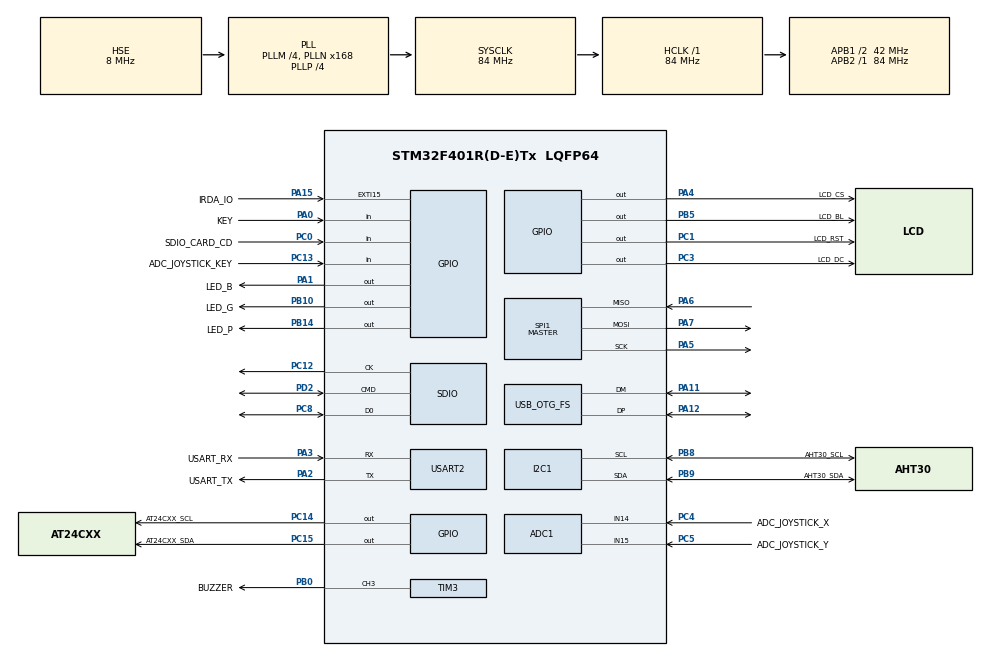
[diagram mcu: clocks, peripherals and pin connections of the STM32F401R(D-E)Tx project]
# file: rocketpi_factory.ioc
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ADC1.Channel-0\#ChannelRegularConversion=ADC_CHANNEL_14
ADC1.Channel-1\#ChannelRegularConversion=ADC_CHANNEL_15
ADC1.ContinuousConvMode=ENABLE
ADC1.EnableAnalogWatchDog=false
ADC1.InjNumberOfConversion=0
ADC1.NbrOfConversion=2
ADC1.NbrOfConversionFlag=1
ADC1.Rank-0\#ChannelRegularConversion=1
ADC1.Rank-1\#ChannelRegularConversion=2
ADC1.SamplingTime-0\#ChannelRegularConversion=ADC_SAMPLETIME_112CYCLES
ADC1.SamplingTime-1\#ChannelRegularConversion=ADC_SAMPLETIME_112CYCLES
ADC1.ScanConvMode=ENABLE
ADC1.master=1
Dma.Request0=SPI1_TX
Dma.Request1=SDIO_RX
Dma.Request2=SDIO_TX
Dma.Request3=USART2_RX
Dma.Request4=USART2_TX
Dma.SDIO_RX.1.Direction=DMA_PERIPH_TO_MEMORY
Dma.SDIO_RX.1.FIFOMode=DMA_FIFOMODE_ENABLE
Dma.SDIO_RX.1.FIFOThreshold=DMA_FIFO_THRESHOLD_FULL
Dma.SDIO_RX.1.Instance=DMA2_Stream6
Dma.SDIO_RX.1.MemBurst=DMA_MBURST_INC4
Dma.SDIO_RX.1.MemDataAlignment=DMA_MDATAALIGN_WORD
Dma.SDIO_RX.1.MemInc=DMA_MINC_ENABLE
Dma.SDIO_RX.1.Mode=DMA_PFCTRL
Dma.SDIO_RX.1.PeriphBurst=DMA_PBURST_INC4
Dma.SDIO_RX.1.PeriphDataAlignment=DMA_PDATAALIGN_WORD
Dma.SDIO_RX.1.PeriphInc=DMA_PINC_DISABLE
Dma.SDIO_RX.1.Priority=DMA_PRIORITY_LOW
Dma.SDIO_TX.2.Direction=DMA_MEMORY_TO_PERIPH
Dma.SDIO_TX.2.FIFOMode=DMA_FIFOMODE_ENABLE
Dma.SDIO_TX.2.FIFOThreshold=DMA_FIFO_THRESHOLD_FULL
Dma.SDIO_TX.2.Instance=DMA2_Stream3
Dma.SDIO_TX.2.MemBurst=DMA_MBURST_INC4
Dma.SDIO_TX.2.MemDataAlignment=DMA_MDATAALIGN_WORD
Dma.SDIO_TX.2.MemInc=DMA_MINC_ENABLE
Dma.SDIO_TX.2.Mode=DMA_PFCTRL
Dma.SDIO_TX.2.PeriphBurst=DMA_PBURST_INC4
Dma.SDIO_TX.2.PeriphDataAlignment=DMA_PDATAALIGN_WORD
Dma.SDIO_TX.2.PeriphInc=DMA_PINC_DISABLE
Dma.SDIO_TX.2.Priority=DMA_PRIORITY_LOW
Dma.SPI1_TX.0.Direction=DMA_MEMORY_TO_PERIPH
Dma.SPI1_TX.0.FIFOMode=DMA_FIFOMODE_DISABLE
Dma.SPI1_TX.0.Instance=DMA2_Stream5
Dma.SPI1_TX.0.MemDataAlignment=DMA_MDATAALIGN_BYTE
Dma.SPI1_TX.0.MemInc=DMA_MINC_ENABLE
Dma.SPI1_TX.0.Mode=DMA_NORMAL
Dma.SPI1_TX.0.PeriphDataAlignment=DMA_PDATAALIGN_BYTE
Dma.SPI1_TX.0.PeriphInc=DMA_PINC_DISABLE
Dma.SPI1_TX.0.Priority=DMA_PRIORITY_LOW
Dma.USART2_RX.3.Direction=DMA_PERIPH_TO_MEMORY
Dma.USART2_RX.3.FIFOMode=DMA_FIFOMODE_DISABLE
Dma.USART2_RX.3.Instance=DMA1_Stream5
Dma.USART2_RX.3.MemDataAlignment=DMA_MDATAALIGN_BYTE
Dma.USART2_RX.3.MemInc=DMA_MINC_ENABLE
Dma.USART2_RX.3.Mode=DMA_NORMAL
Dma.USART2_RX.3.PeriphDataAlignment=DMA_PDATAALIGN_BYTE
Dma.USART2_RX.3.PeriphInc=DMA_PINC_DISABLE
Dma.USART2_RX.3.Priority=DMA_PRIORITY_LOW
Dma.USART2_TX.4.Direction=DMA_MEMORY_TO_PERIPH
Dma.USART2_TX.4.FIFOMode=DMA_FIFOMODE_DISABLE
Dma.USART2_TX.4.Instance=DMA1_Stream6
Dma.USART2_TX.4.MemDataAlignment=DMA_MDATAALIGN_BYTE
Dma.USART2_TX.4.MemInc=DMA_MINC_ENABLE
Dma.USART2_TX.4.Mode=DMA_NORMAL
Dma.USART2_TX.4.PeriphDataAlignment=DMA_PDATAALIGN_BYTE
Dma.USART2_TX.4.PeriphInc=DMA_PINC_DISABLE
Dma.USART2_TX.4.Priority=DMA_PRIORITY_LOW
FATFS.BSP.number=1
FATFS.USE_DMA_CODE_SD=1
FATFS0.BSP.STBoard=false
FATFS0.BSP.api=Unknown
FATFS0.BSP.instance=PC0
FATFS0.BSP.ip=GPIO
FATFS0.BSP.mode=Input
FATFS0.BSP.name=Detect_SDIO
FATFS0.BSP.solution=PC0
FREERTOS.Tasks01=defaultTask,24,128,StartDefaultTask,Default,NULL,Dynamic,NULL,NULL
Mcu.Family=STM32F4
Mcu.Name=STM32F401R(D-E)Tx
Mcu.Package=LQFP64
NVIC.DMA1_Stream5_IRQn=true\:5\:0\:false\:false\:true\:true\:false\:true\:true
NVIC.DMA1_Stream6_IRQn=true\:5\:0\:false\:false\:true\:true\:false\:true\:true
NVIC.DMA2_Stream3_IRQn=true\:5\:0\:false\:false\:true\:true\:false\:true\:true
NVIC.DMA2_Stream5_IRQn=true\:5\:0\:false\:false\:true\:true\:false\:true\:true
NVIC.DMA2_Stream6_IRQn=true\:5\:0\:false\:false\:true\:true\:false\:true\:true
NVIC.EXTI15_10_IRQn=true\:5\:0\:false\:false\:true\:true\:true\:true\:true
NVIC.OTG_FS_IRQn=true\:5\:0\:false\:false\:true\:true\:true\:true\:true
NVIC.PriorityGroup=NVIC_PRIORITYGROUP_4
NVIC.SDIO_IRQn=true\:5\:0\:false\:false\:true\:true\:true\:true\:true
NVIC.SPI1_IRQn=true\:5\:0\:false\:false\:true\:true\:true\:true\:true
NVIC.TIM1_BRK_TIM9_IRQn=true\:5\:0\:false\:false\:true\:true\:false\:true\:true
NVIC.TIM1_UP_TIM10_IRQn=true\:5\:0\:false\:false\:true\:true\:true\:true\:true
NVIC.TimeBase=TIM1_BRK_TIM9_IRQn
NVIC.TimeBaseIP=TIM9
NVIC.USART2_IRQn=true\:5\:0\:false\:false\:true\:true\:true\:true\:true
PA0-WKUP.GPIO_Label=KEY
PA0-WKUP.Signal=GPIO_Input
PA1.GPIO_Label=LED_B
PA1.PinState=GPIO_PIN_SET
PA1.Signal=GPIO_Output
PA11.Mode=Device_Only
PA11.Signal=USB_OTG_FS_DM
PA12.Mode=Device_Only
PA12.Signal=USB_OTG_FS_DP
PA13.GPIO_Label=TMS
PA13.Mode=Serial_Wire
PA13.Signal=SYS_JTMS-SWDIO
PA14.GPIO_Label=TCK
PA14.Mode=Serial_Wire
PA14.Signal=SYS_JTCK-SWCLK
PA15.GPIO_Label=IRDA_IO
PA15.GPIO_ModeDefaultEXTI=GPIO_MODE_IT_RISING_FALLING
PA15.GPIO_PuPd=GPIO_PULLUP
PA15.Signal=GPXTI15
PA2.GPIO_Label=USART_TX
PA2.GPIO_Mode=GPIO_MODE_AF_PP
PA2.GPIO_PuPd=GPIO_NOPULL
PA2.GPIO_Speed=GPIO_SPEED_FREQ_LOW
PA2.Mode=Asynchronous
PA2.Signal=USART2_TX
PA3.GPIO_Label=USART_RX
PA3.GPIO_Mode=GPIO_MODE_AF_PP
PA3.GPIO_PuPd=GPIO_NOPULL
PA3.GPIO_Speed=GPIO_SPEED_FREQ_LOW
PA3.Mode=Asynchronous
PA3.Signal=USART2_RX
PA4.GPIO_Label=LCD_CS
PA4.Signal=GPIO_Output
PA5.Mode=Full_Duplex_Master
PA5.Signal=SPI1_SCK
PA6.Mode=Full_Duplex_Master
PA6.Signal=SPI1_MISO
PA7.Mode=Full_Duplex_Master
PA7.Signal=SPI1_MOSI
PB0.GPIO_Label=BUZZER
PB0.Signal=S_TIM3_CH3
PB10.GPIO_Label=LED_G
PB10.PinState=GPIO_PIN_SET
PB10.Signal=GPIO_Output
PB14.GPIO_Label=LED_P
PB14.PinState=GPIO_PIN_SET
PB14.Signal=GPIO_Output
PB5.GPIO_Label=LCD_BL
PB5.Signal=GPIO_Output
PB8.GPIO_Label=AHT30_SCL
PB8.GPIO_Speed=GPIO_SPEED_FREQ_LOW
PB8.Mode=I2C
PB8.Signal=I2C1_SCL
PB9.GPIO_Label=AHT30_SDA
PB9.GPIO_Speed=GPIO_SPEED_FREQ_LOW
PB9.Mode=I2C
PB9.Signal=I2C1_SDA
PC0.GPIO_Label=SDIO_CARD_CD
PC0.Signal=GPIO_Input
PC1.GPIO_Label=LCD_RST
PC1.Signal=GPIO_Output
PC12.Mode=SD_1_bit
PC12.Signal=SDIO_CK
PC13-ANTI_TAMP.GPIO_Label=ADC_JOYSTICK_KEY
PC13-ANTI_TAMP.Signal=GPIO_Input
PC14-OSC32_IN.GPIO_Label=AT24CXX_SCL
PC14-OSC32_IN.PinState=GPIO_PIN_SET
PC14-OSC32_IN.Signal=GPIO_Output
PC15-OSC32_OUT.GPIO_Label=AT24CXX_SDA
PC15-OSC32_OUT.PinState=GPIO_PIN_SET
PC15-OSC32_OUT.Signal=GPIO_Output
PC3.GPIO_Label=LCD_DC
PC3.Signal=GPIO_Output
PC4.GPIO_Label=ADC_JOYSTICK_X
PC4.Signal=ADCx_IN14
PC5.GPIO_Label=ADC_JOYSTICK_Y
PC5.Signal=ADCx_IN15
PC8.Mode=SD_1_bit
PC8.Signal=SDIO_D0
PD2.Mode=SD_1_bit
PD2.Signal=SDIO_CMD
PH0\ -\ OSC_IN.Mode=HSE-External-Oscillator
PH0\ -\ OSC_IN.Signal=RCC_OSC_IN
PH1\ -\ OSC_OUT.Mode=HSE-External-Oscillator
PH1\ -\ OSC_OUT.Signal=RCC_OSC_OUT
ProjectManager.HeapSize=0x1000
ProjectManager.StackSize=0x1000
ProjectManager.TargetToolchain=MDK-ARM V5.27
RCC.48MHZClocksFreq_Value=48000000
RCC.AHBFreq_Value=84000000
RCC.APB1CLKDivider=RCC_HCLK_DIV2
RCC.APB1Freq_Value=42000000
RCC.APB1TimFreq_Value=84000000
RCC.APB2Freq_Value=84000000
RCC.APB2TimFreq_Value=84000000
RCC.CortexFreq_Value=84000000
RCC.HCLKFreq_Value=84000000
RCC.HSE_VALUE=8000000
RCC.HSI_VALUE=16000000
RCC.LSE_VALUE=32768
RCC.PLLM=4
RCC.PLLN=168
RCC.PLLP=RCC_PLLP_DIV4
RCC.PLLQ=7
RCC.SYSCLKFreq_VALUE=84000000
RCC.SYSCLKSource=RCC_SYSCLKSOURCE_PLLCLK
RCC.VCOOutputFreq_Value=336000000
SH.ADCx_IN14.0=ADC1_IN14,IN14
SH.ADCx_IN15.0=ADC1_IN15,IN15
SH.S_TIM3_CH3.0=TIM3_CH3,PWM Generation3 CH3
SPI1.DataSize=SPI_DATASIZE_8BIT
SPI1.Direction=SPI_DIRECTION_2LINES
SPI1.Mode=SPI_MODE_MASTER
SPI1.VirtualType=VM_MASTER
TIM1.Prescaler=84-1
TIM3.Channel-PWM\ Generation3\ CH3=TIM_CHANNEL_3
TIM3.ClockDivision=TIM_CLOCKDIVISION_DIV1
TIM3.Period=369
TIM3.Prescaler=84-1
TIM3.Pulse-PWM\ Generation3\ CH3=185
USART2.VirtualMode=VM_ASYNC
USB_DEVICE.CLASS_NAME_FS=CDC
USB_DEVICE.VirtualMode-CDC_FS=Cdc
USB_DEVICE.VirtualModeFS=Cdc_FS
USB_OTG_FS.VirtualMode=Device_Only
VP_FATFS_VS_SDIO.Mode=SDIO
VP_FREERTOS_VS_CMSIS_V2.Mode=CMSIS_V2
VP_SYS_VS_tim9.Mode=TIM9
VP_TIM1_VS_ClockSourceINT.Mode=Internal
VP_USB_DEVICE_VS_USB_DEVICE_CDC_FS.Mode=CDC_FS
board=NUCLEO-F401RE

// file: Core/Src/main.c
/* USER CODE BEGIN Header */
/**
  ******************************************************************************
  * @file           : main.c
  * @brief          : Main program body
  ******************************************************************************
  * @attention
  *
  * Copyright (c) 2025 STMicroelectronics.
  * All rights reserved.
  *
  * This software is licensed under terms that can be found in the LICENSE file
  * in the root directory of this software component.
  * If no LICENSE file comes with this software, it is provided AS-IS.
  *
  ******************************************************************************
  */
/* USER CODE END Header */
#include "main.h"
#include "cmsis_os.h"
#include "adc.h"
#include "dma.h"
#include "fatfs.h"
#include "i2c.h"
#include "sdio.h"
#include "spi.h"
#include "tim.h"
#include "usart.h"
#include "usb_device.h"
#include "gpio.h"

/* USER CODE BEGIN Includes */
#include "lvgl.h"
/* USER CODE END Includes */

void SystemClock_Config(void);
void MX_FREERTOS_Init(void);

int main(void)
{

  /* MCU Configuration--------------------------------------------------------*/

  /* Reset of all peripherals, Initializes the Flash interface and the Systick. */
  HAL_Init();

  /* Configure the system clock */
  SystemClock_Config();

  /* Initialize all configured peripherals */
  MX_GPIO_Init();
  MX_DMA_Init();
  MX_USART2_UART_Init();
  MX_SPI1_Init();
  MX_ADC1_Init();
  MX_TIM3_Init();
  MX_I2C1_Init();
  MX_SDIO_SD_Init();
  MX_FATFS_Init();
  MX_TIM1_Init();

  /* Init scheduler */
  osKernelInitialize();

  /* Call init function for freertos objects (in cmsis_os2.c) */
  MX_FREERTOS_Init();

  /* Start scheduler */
  osKernelStart();

  /* We should never get here as control is now taken by the scheduler */

  /* Infinite loop */
  while (1)
  {

  }
}

void SystemClock_Config(void)
{
  RCC_OscInitTypeDef RCC_OscInitStruct = {0};
  RCC_ClkInitTypeDef RCC_ClkInitStruct = {0};

  /** Configure the main internal regulator output voltage
  */
  __HAL_RCC_PWR_CLK_ENABLE();
  __HAL_PWR_VOLTAGESCALING_CONFIG(PWR_REGULATOR_VOLTAGE_SCALE2);

  /** Initializes the RCC Oscillators according to the specified parameters
  * in the RCC_OscInitTypeDef structure.
  */
  RCC_OscInitStruct.OscillatorType = RCC_OSCILLATORTYPE_HSE;
  RCC_OscInitStruct.HSEState = RCC_HSE_ON;
  RCC_OscInitStruct.PLL.PLLState = RCC_PLL_ON;
  RCC_OscInitStruct.PLL.PLLSource = RCC_PLLSOURCE_HSE;
  RCC_OscInitStruct.PLL.PLLM = 4;
  RCC_OscInitStruct.PLL.PLLN = 168;
  RCC_OscInitStruct.PLL.PLLP = RCC_PLLP_DIV4;
  RCC_OscInitStruct.PLL.PLLQ = 7;
  if (HAL_RCC_OscConfig(&RCC_OscInitStruct) != HAL_OK)
  {
    Error_Handler();
  }

  /** Initializes the CPU, AHB and APB buses clocks
  */
  RCC_ClkInitStruct.ClockType = RCC_CLOCKTYPE_HCLK|RCC_CLOCKTYPE_SYSCLK
                              |RCC_CLOCKTYPE_PCLK1|RCC_CLOCKTYPE_PCLK2;
  RCC_ClkInitStruct.SYSCLKSource = RCC_SYSCLKSOURCE_PLLCLK;
  RCC_ClkInitStruct.AHBCLKDivider = RCC_SYSCLK_DIV1;
  RCC_ClkInitStruct.APB1CLKDivider = RCC_HCLK_DIV2;
  RCC_ClkInitStruct.APB2CLKDivider = RCC_HCLK_DIV1;

  if (HAL_RCC_ClockConfig(&RCC_ClkInitStruct, FLASH_LATENCY_2) != HAL_OK)
  {
    Error_Handler();
  }
}

/* USER CODE BEGIN 4 */

extern void irda_tim_irq(TIM_HandleTypeDef *htim);
/* USER CODE END 4 */

void HAL_TIM_PeriodElapsedCallback(TIM_HandleTypeDef *htim)
{
  if (htim->Instance == TIM9)
  {
    HAL_IncTick();
  }
  /* USER CODE BEGIN Callback 1 */

	 lv_tick_inc(1);
	 irda_tim_irq(htim);
  /* USER CODE END Callback 1 */
}

void Error_Handler(void)
{
  __disable_irq();
  while (1)
  {
  }
}

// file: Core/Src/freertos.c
/* USER CODE BEGIN Header */
/**
  ******************************************************************************
  * File Name          : freertos.c
  * Description        : Code for freertos applications
  ******************************************************************************
  * @attention
  *
  * Copyright (c) 2025 STMicroelectronics.
  * All rights reserved.
  *
  * This software is licensed under terms that can be found in the LICENSE file
  * in the root directory of this software component.
  * If no LICENSE file comes with this software, it is provided AS-IS.
  *
  ******************************************************************************
  */
/* USER CODE END Header */

#include "FreeRTOS.h"
#include "task.h"
#include "main.h"
#include "cmsis_os.h"

/* USER CODE BEGIN Includes */
#include "app.h"
/* USER CODE END Includes */

/* Definitions for defaultTask */
osThreadId_t defaultTaskHandle;
const osThreadAttr_t defaultTask_attributes = {
  .name = "defaultTask",
  .stack_size = 128 * 4,
  .priority = (osPriority_t) osPriorityHigh,
};

void StartDefaultTask(void *argument);

extern void MX_USB_DEVICE_Init(void);
void MX_FREERTOS_Init(void); /* (MISRA C 2004 rule 8.1) */

void MX_FREERTOS_Init(void) {

  /* Create the thread(s) */
  /* creation of defaultTask */
  defaultTaskHandle = osThreadNew(StartDefaultTask, NULL, &defaultTask_attributes);

}

void StartDefaultTask(void *argument)
{
  /* init code for USB_DEVICE */
  MX_USB_DEVICE_Init();
  /* USER CODE BEGIN StartDefaultTask */
	app();

  /* Infinite loop */
  for(;;)
  {
    osDelay(1000);
  }
  /* USER CODE END StartDefaultTask */
}
